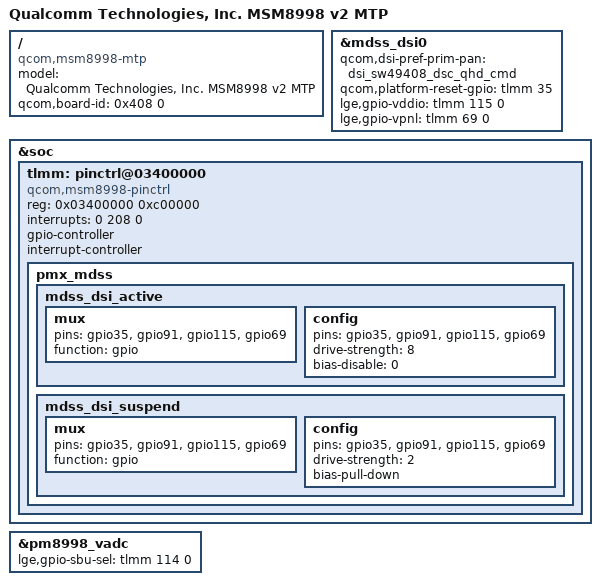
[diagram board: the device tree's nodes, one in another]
/* Copyright (c) 2016, The Linux Foundation. All rights reserved.
 *
 * This program is free software; you can redistribute it and/or modify
 * it under the terms of the GNU General Public License version 2 and
 * only version 2 as published by the Free Software Foundation.
 *
 * This program is distributed in the hope that it will be useful,
 * but WITHOUT ANY WARRANTY; without even the implied warranty of
 * MERCHANTABILITY or FITNESS FOR A PARTICULAR PURPOSE.  See the
 * GNU General Public License for more details.
 */


/dts-v1/;

#include "../../../qcom/msm8998-v2.dtsi"
#include "msm8998-lucy_kr.dtsi"

/ {
	model = "Qualcomm Technologies, Inc. MSM8998 v2 MTP";
	compatible = "qcom,msm8998-mtp", "qcom,msm8998", "qcom,mtp";
	qcom,board-id = <0x408 0>;
};


&mdss_dsi0 {
        qcom,dsi-pref-prim-pan = <&dsi_sw49408_dsc_qhd_cmd>;
        qcom,platform-reset-gpio = <&tlmm 35 0>;
	lge,gpio-vddio = <&tlmm 115 0>;
	lge,gpio-vpnl = <&tlmm 69 0>;
};

/* pinctrl for Display function
 * GPIO35 : LCD_RESET_N
 * GPIO115 : LCD_VDD_IO_EN
 * GPIO69 : LCD_VCL_EN
 */

&soc {
	tlmm: pinctrl@03400000 {
		compatible = "qcom,msm8998-pinctrl";
		reg = <0x03400000 0xc00000>;
		interrupts = <0 208 0>;
		gpio-controller;
		#gpio-cells = <2>;
		interrupt-controller;
		#interrupt-cells = <2>;

		pmx_mdss: pmx_mdss {
			mdss_dsi_active: mdss_dsi_active {
				mux {
					pins = "gpio35", "gpio91", "gpio115", "gpio69";
					function = "gpio";
				};

				config {
					pins = "gpio35", "gpio91", "gpio115", "gpio69";
					drive-strength = <8>; /* 8 mA */
					bias-disable = <0>; /* no pull */
				};
			};
			mdss_dsi_suspend: mdss_dsi_suspend {
				mux {
					pins = "gpio35", "gpio91", "gpio115", "gpio69";
					function = "gpio";
				};

				config {
					pins = "gpio35", "gpio91", "gpio115", "gpio69";
					drive-strength = <2>; /* 2 mA */
					bias-pull-down; /* pull down */
				};
			};
		};
	};
};

&pm8998_vadc {
	lge,gpio-sbu-sel = <&tlmm 114 0>;
};
